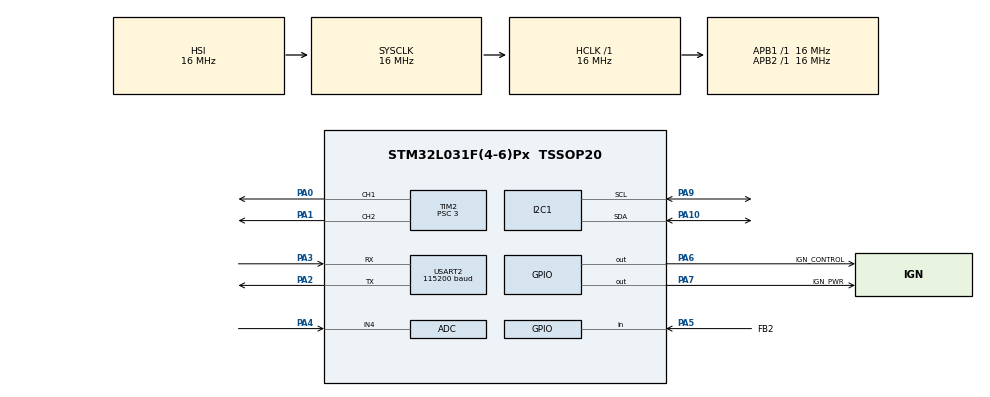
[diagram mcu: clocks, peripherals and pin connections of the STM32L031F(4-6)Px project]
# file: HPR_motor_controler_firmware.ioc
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ADC.SamplingTime=ADC_SAMPLETIME_12CYCLES_5
I2C1.OwnAddress=1
I2C1.Timing=0x00303D5B
Mcu.Family=STM32L0
Mcu.Name=STM32L031F(4-6)Px
Mcu.Package=TSSOP20
NVIC.I2C1_IRQn=true\:0\:0\:false\:false\:true\:true\:true\:true
NVIC.USART2_IRQn=true\:0\:0\:false\:false\:true\:true\:true\:true
PA0-CK_IN.Signal=S_TIM2_CH1
PA1.Signal=S_TIM2_CH2
PA10.GPIO_Pu=GPIO_PULLUP
PA10.Mode=I2C
PA10.Signal=I2C1_SDA
PA13.Mode=Serial_Wire
PA13.Signal=SYS_SWDIO
PA14.Mode=Serial_Wire
PA14.Signal=SYS_SWCLK
PA2.Mode=Asynchronous
PA2.Signal=USART2_TX
PA3.Mode=Asynchronous
PA3.Signal=USART2_RX
PA4.Mode=IN4
PA4.Signal=ADC_IN4
PA5.GPIO_Label=FB2
PA5.Signal=GPIO_Input
PA6.GPIO_Label=IGN_CONTROL
PA6.Signal=GPIO_Output
PA7.GPIO_Label=IGN_PWR
PA7.Signal=GPIO_Output
PA9.GPIO_Pu=GPIO_PULLUP
PA9.Mode=I2C
PA9.Signal=I2C1_SCL
ProjectManager.HeapSize=0x200
ProjectManager.StackSize=0x400
ProjectManager.TargetToolchain=Makefile
RCC.ADCFreq_Value=16000000
RCC.AHBFreq_Value=16000000
RCC.APB1Freq_Value=16000000
RCC.APB1TimFreq_Value=16000000
RCC.APB2Freq_Value=16000000
RCC.APB2TimFreq_Value=16000000
RCC.HCLKFreq_Value=16000000
RCC.HSE_VALUE=8000000
RCC.HSI16_VALUE=16000000
RCC.HSI_VALUE=16000000
RCC.LSE_VALUE=32768
RCC.MSI_VALUE=2097000
RCC.SYSCLKFreq_VALUE=16000000
RCC.SYSCLKSource=RCC_SYSCLKSOURCE_HSI
RCC.VCOOutputFreq_Value=48000000
SH.S_TIM2_CH1.0=TIM2_CH1,PWM Generation1 CH1
SH.S_TIM2_CH2.0=TIM2_CH2,PWM Generation2 CH2
TIM2.AutoReloadPreload=TIM_AUTORELOAD_PRELOAD_ENABLE
TIM2.Channel-PWM\ Generation1\ CH1=TIM_CHANNEL_1
TIM2.Channel-PWM\ Generation2\ CH2=TIM_CHANNEL_2
TIM2.Period=39999
TIM2.Prescaler=3
USART2.BaudRate=115200
USART2.Parity=PARITY_NONE
USART2.VirtualMode-Asynchronous=VM_ASYNC
VP_TIM2_VS_ClockSourceINT.Mode=Internal
board=custom

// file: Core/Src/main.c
/* USER CODE BEGIN Header */
/**
 ******************************************************************************
 * @file           : main.c
 * @brief          : Main program body
 ******************************************************************************
 * @attention
 *
 * <h2><center>&copy; Copyright (c) 2021 STMicroelectronics.
 * All rights reserved.</center></h2>
 *
 * This software component is licensed by ST under BSD 3-Clause license,
 * the "License"; You may not use this file except in compliance with the
 * License. You may obtain a copy of the License at:
 *                        opensource.org/licenses/BSD-3-Clause
 *
 ******************************************************************************
 */
/* USER CODE END Header */
#include "main.h"
#include "adc.h"
#include "i2c.h"
#include "tim.h"
#include "usart.h"
#include "gpio.h"

/* USER CODE BEGIN Includes */
#include "fsm.h"
#include "pwm.h"
/* USER CODE END Includes */

void SystemClock_Config(void);

int main(void)
{
  /* USER CODE BEGIN 1 */
    eFsmPeripheriesData periData;
  /* USER CODE END 1 */

  /* MCU Configuration--------------------------------------------------------*/

  /* Reset of all peripherals, Initializes the Flash interface and the Systick. */
  HAL_Init();

  /* USER CODE BEGIN Init */
  FSM_init();
  /* USER CODE END Init */

  /* Configure the system clock */
  SystemClock_Config();

  /* Initialize all configured peripherals */
  MX_GPIO_Init();
  MX_I2C1_Init();
  MX_USART2_UART_Init();
  MX_TIM2_Init();
  MX_ADC_Init();
  /* USER CODE BEGIN 2 */
  PWM1_start();
  /* USER CODE END 2 */

  /* Infinite loop */
  while (1)
  {

    /* USER CODE BEGIN 3 */
    FSM_reciveCMD(&huart2);
    // Update FSM TODO
    // Run FSM logic
    FSM_step(&periData);
  }
  /* USER CODE END 3 */
}

void SystemClock_Config(void)
{
  RCC_OscInitTypeDef RCC_OscInitStruct = {0};
  RCC_ClkInitTypeDef RCC_ClkInitStruct = {0};
  RCC_PeriphCLKInitTypeDef PeriphClkInit = {0};

  /** Configure the main internal regulator output voltage
  */
  __HAL_PWR_VOLTAGESCALING_CONFIG(PWR_REGULATOR_VOLTAGE_SCALE1);

  /** Initializes the RCC Oscillators according to the specified parameters
  * in the RCC_OscInitTypeDef structure.
  */
  RCC_OscInitStruct.OscillatorType = RCC_OSCILLATORTYPE_HSI;
  RCC_OscInitStruct.HSIState = RCC_HSI_ON;
  RCC_OscInitStruct.HSICalibrationValue = RCC_HSICALIBRATION_DEFAULT;
  RCC_OscInitStruct.PLL.PLLState = RCC_PLL_NONE;
  if (HAL_RCC_OscConfig(&RCC_OscInitStruct) != HAL_OK)
  {
    Error_Handler();
  }

  /** Initializes the CPU, AHB and APB buses clocks
  */
  RCC_ClkInitStruct.ClockType = RCC_CLOCKTYPE_HCLK|RCC_CLOCKTYPE_SYSCLK
                              |RCC_CLOCKTYPE_PCLK1|RCC_CLOCKTYPE_PCLK2;
  RCC_ClkInitStruct.SYSCLKSource = RCC_SYSCLKSOURCE_HSI;
  RCC_ClkInitStruct.AHBCLKDivider = RCC_SYSCLK_DIV1;
  RCC_ClkInitStruct.APB1CLKDivider = RCC_HCLK_DIV1;
  RCC_ClkInitStruct.APB2CLKDivider = RCC_HCLK_DIV1;

  if (HAL_RCC_ClockConfig(&RCC_ClkInitStruct, FLASH_LATENCY_0) != HAL_OK)
  {
    Error_Handler();
  }
  PeriphClkInit.PeriphClockSelection = RCC_PERIPHCLK_USART2|RCC_PERIPHCLK_I2C1;
  PeriphClkInit.Usart2ClockSelection = RCC_USART2CLKSOURCE_PCLK1;
  PeriphClkInit.I2c1ClockSelection = RCC_I2C1CLKSOURCE_PCLK1;
  if (HAL_RCCEx_PeriphCLKConfig(&PeriphClkInit) != HAL_OK)
  {
    Error_Handler();
  }
}

void Error_Handler(void)
{
    __disable_irq();
    while (1)
    {
    }
}
